# STM32F429x register map
File version: 1.0
Registers are 32-bit, read-write, reset 0x0 unless marked. A register's access mark holds for its fields unless they carry their own. Offsets are from the block's base; [hi:lo] are bit positions; {n}, {i} and the like mark numbered series; 'fields as' and 'values as' point back to an identical list.

## NVIC — Nested Vectored Interrupt Controller
Base 0xE000E000
0x04 ICTR ro — Interrupt Controller Type Register
  [3:0] INTLINESNUM — Total number of interrupt lines in groups
{0x100+4i} ISER{i} (i=0..2) — Interrupt Set-Enable Register
  [31:0] SETENA
{0x180+4i} ICER{i} (i=0..2) — Interrupt Clear-Enable Register
  [31:0] CLRENA
{0x200+4i} ISPR{i} (i=0..2) — Interrupt Set-Pending Register
  [31:0] SETPEND
{0x280+4i} ICPR{i} (i=0..2) — Interrupt Clear-Pending Register
  [31:0] CLRPEND
{0x300+4i} IABR{i} ro (i=0..2) — Interrupt Active Bit Register
  [31:0] ACTIVE
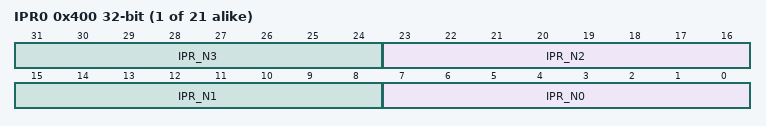
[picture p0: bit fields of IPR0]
{0x400+4i} IPR{i} (i=0..20) — Interrupt Priority Register
  [8n+7:8n] IPR_N{n} (n=0..3)
0xF00 STIR wo — Software Triggered Interrupt Register
  [8:0] INTID — interrupt to be triggered

## FLASH
Base 0x40023C00
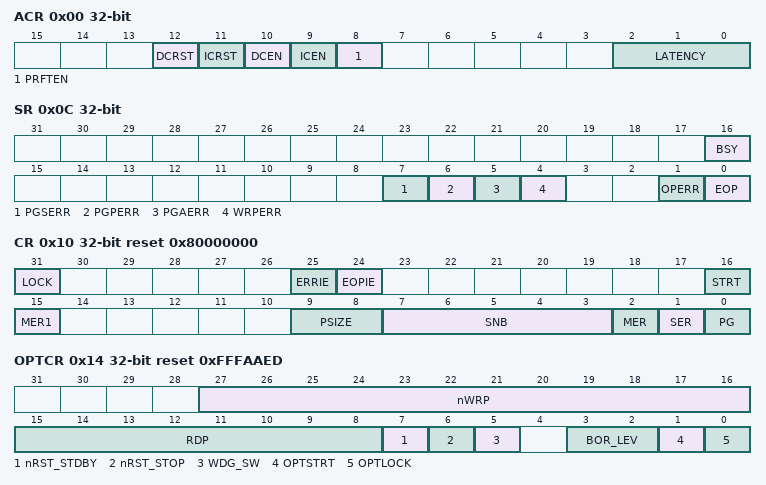
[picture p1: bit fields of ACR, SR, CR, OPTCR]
0x00 ACR access per field — Flash access control register
  [12] DCRST rw — Data cache reset
  [11] ICRST wo — Instruction cache reset
  [10] DCEN rw — Data cache enable
  [9] ICEN rw — Instruction cache enable
  [8] PRFTEN rw — Prefetch enable
  [2:0] LATENCY rw
0x04 KEYR wo — Flash key register
  [31:0] KEY — FPEC key
0x08 OPTKEYR wo — Flash option key register
  [31:0] OPTKEY — Option byte key
0x0C SR access per field — Status register
  [16] BSY ro — Busy
  [7] PGSERR rw — Programming sequence error
  [6] PGPERR rw — Programming parallelism error
  [5] PGAERR rw — Programming alignment error
  [4] WRPERR rw — Write protection error
  [1] OPERR rw — Operation error
  [0] EOP rw — End of operation
0x10 CR reset 0x80000000 — Control register
  [31] LOCK
  [25] ERRIE — Error interrupt enable
  [24] EOPIE — End of operation interrupt enable
  [16] STRT — Start
  [15] MER1 — Mass Erase of sectors 12 to 23
  [9:8] PSIZE — Program size
  [7:3] SNB — Sector number
  [2] MER — Mass Erase of sectors 0 to 11
  [1] SER — Sector Erase
  [0] PG — Programming
0x14 OPTCR reset 0xFFFAAED — Flash option control register
  [27:16] nWRP — Not write protect
  [15:8] RDP — Read protect
  [7] nRST_STDBY — nRST_STDBY User option bytes
  [6] nRST_STOP — nRST_STOP User option bytes
  [5] WDG_SW — WDG_SW User option bytes
  [3:2] BOR_LEV — BOR reset Level
  [1] OPTSTRT — Option start
  [0] OPTLOCK — Option lock
0x18 OPTCR1 reset 0xFFF0000 — Flash option control register 1
  [27:16] nWRP — Not write protect

## EXTI — External interrupt/event controller
Base 0x40013C00
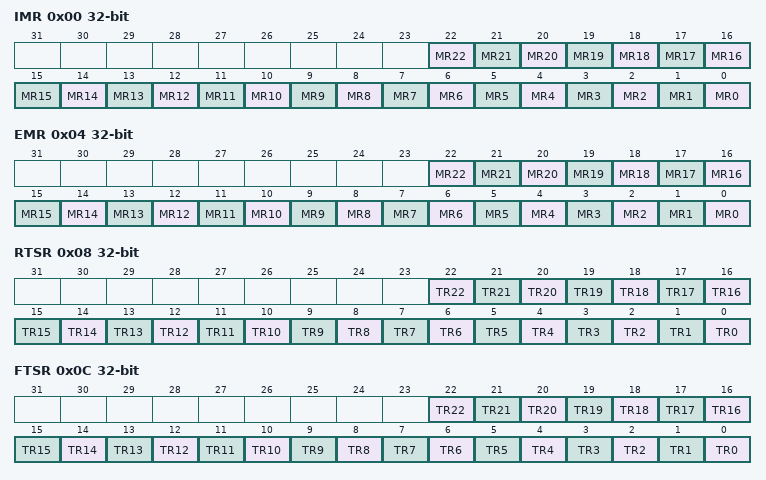
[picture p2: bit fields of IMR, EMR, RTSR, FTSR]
0x00 IMR — Interrupt mask register (EXTI_IMR)
  [n] MR{n} (n=0..22) — Interrupt Mask on line {n}
0x04 EMR — Event mask register (EXTI_EMR)
  [n] MR{n} (n=0..22) — Event Mask on line {n}
0x08 RTSR — Rising Trigger selection register (EXTI_RTSR)
  [n] TR{n} (n=0..22) — Rising trigger event configuration of line {n}
0x0C FTSR — Falling Trigger selection register (EXTI_FTSR)
  [n] TR{n} (n=0..22) — Falling trigger event configuration of line {n}
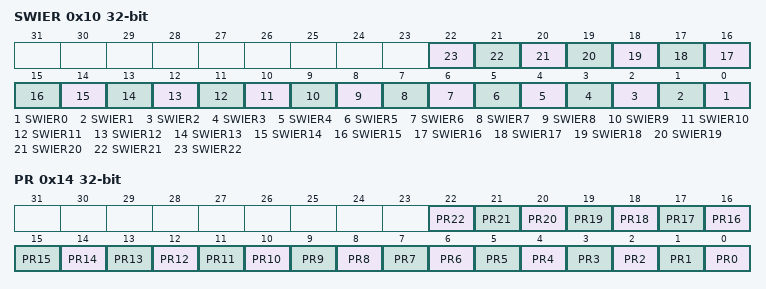
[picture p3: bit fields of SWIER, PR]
0x10 SWIER — Software interrupt event register (EXTI_SWIER)
  [n] SWIER{n} (n=0..22) — Software Interrupt on line {n}
0x14 PR — Pending register (EXTI_PR)
  [n] PR{n} (n=0..22) — Pending bit {n}

## OTG_HS_PWRCLK — USB on the go high speed
Base 0x40040E00
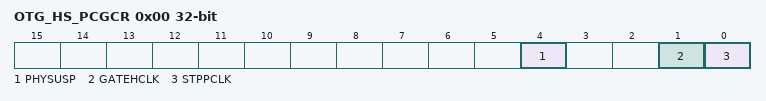
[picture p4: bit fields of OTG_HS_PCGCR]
0x00 OTG_HS_PCGCR — Power and clock gating control register
  [4] PHYSUSP — PHY suspended
  [1] GATEHCLK
  [0] STPPCLK — Stop PHY clock

## DMA2D — DMA2D controller
Base 0x4002B000
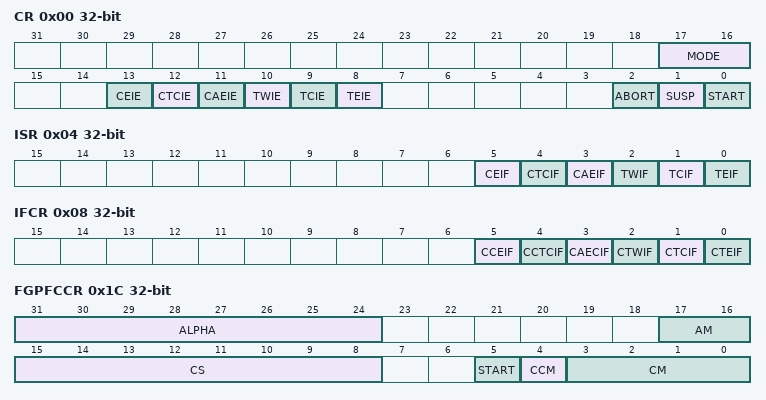
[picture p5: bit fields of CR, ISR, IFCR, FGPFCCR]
0x00 CR — control register
  [17:16] MODE — DMA2D mode
  [13] CEIE — Configuration Error Interrupt Enable
  [12] CTCIE — CLUT transfer complete interrupt enable
  [11] CAEIE — CLUT access error interrupt enable
  [10] TWIE — Transfer watermark interrupt enable
  [9] TCIE — Transfer complete interrupt enable
  [8] TEIE — Transfer error interrupt enable
  [2] ABORT
  [1] SUSP — Suspend
  [0] START
0x04 ISR ro — Interrupt Status Register
  [5] CEIF — Configuration error interrupt flag
  [4] CTCIF — CLUT transfer complete interrupt flag
  [3] CAEIF — CLUT access error interrupt flag
  [2] TWIF — Transfer watermark interrupt flag
  [1] TCIF — Transfer complete interrupt flag
  [0] TEIF — Transfer error interrupt flag
0x08 IFCR — interrupt flag clear register
  [5] CCEIF — Clear configuration error interrupt flag
  [4] CCTCIF — Clear CLUT transfer complete interrupt flag
  [3] CAECIF — Clear CLUT access error interrupt flag
  [2] CTWIF — Clear transfer watermark interrupt flag
  [1] CTCIF — Clear transfer complete interrupt flag
  [0] CTEIF — Clear Transfer error interrupt flag
0x0C FGMAR — foreground memory address register
  [31:0] MA — Memory address
0x10 FGOR — foreground offset register
  [13:0] LO — Line offset
0x14 BGMAR — background memory address register
  [31:0] MA — Memory address
0x18 BGOR — background offset register
  [13:0] LO — Line offset
0x1C FGPFCCR — foreground PFC control register
  [31:24] ALPHA — Alpha value
  [17:16] AM — Alpha mode
  [15:8] CS — CLUT size
  [5] START
  [4] CCM — CLUT color mode
  [3:0] CM — Color mode
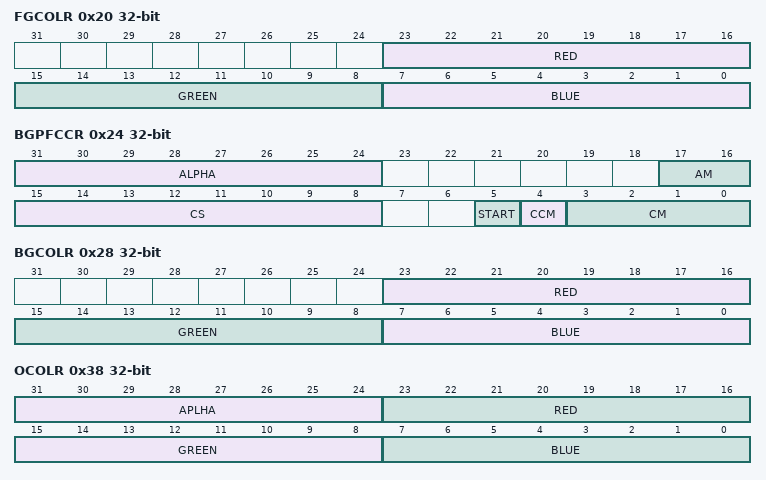
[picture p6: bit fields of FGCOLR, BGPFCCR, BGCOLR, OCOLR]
0x20 FGCOLR — foreground color register
  [23:16] RED — Red Value
  [15:8] GREEN — Green Value
  [7:0] BLUE — Blue Value
0x24 BGPFCCR — background PFC control register
  [31:24] ALPHA — Alpha value
  [17:16] AM — Alpha mode
  [15:8] CS — CLUT size
  [5] START
  [4] CCM — CLUT Color mode
  [3:0] CM — Color mode
0x28 BGCOLR — background color register
  fields as FGCOLR
0x2C FGCMAR — foreground CLUT memory address register
  [31:0] MA — Memory Address
0x30 BGCMAR — background CLUT memory address register
  [31:0] MA — Memory address
0x34 OPFCCR — output PFC control register
  [2:0] CM — Color mode
0x38 OCOLR — output color register
  [31:24] APLHA — Alpha Channel Value
  [23:16] RED — Red Value
  [15:8] GREEN — Green Value
  [7:0] BLUE — Blue Value
0x3C OMAR — output memory address register
  [31:0] MA — Memory Address
0x40 OOR — output offset register
  [13:0] LO — Line Offset
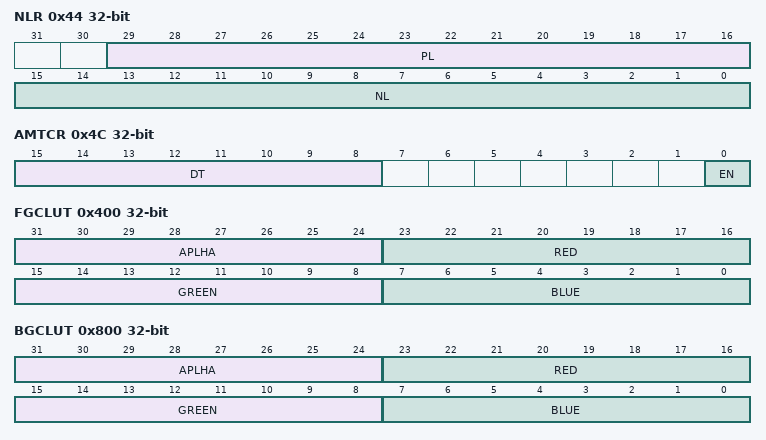
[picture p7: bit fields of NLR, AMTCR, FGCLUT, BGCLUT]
0x44 NLR — number of line register
  [29:16] PL — Pixel per lines
  [15:0] NL — Number of lines
0x48 LWR — line watermark register
  [15:0] LW — Line watermark
0x4C AMTCR — AHB master timer configuration register
  [15:8] DT — Dead Time
  [0] EN — Enable
0x400 FGCLUT
  [31:24] APLHA, [23:16] RED, [15:8] GREEN, [7:0] BLUE
0x800 BGCLUT
  [31:24] APLHA, [23:16] RED, [15:8] GREEN, [7:0] BLUE

## PWR — Power control
Base 0x40007000
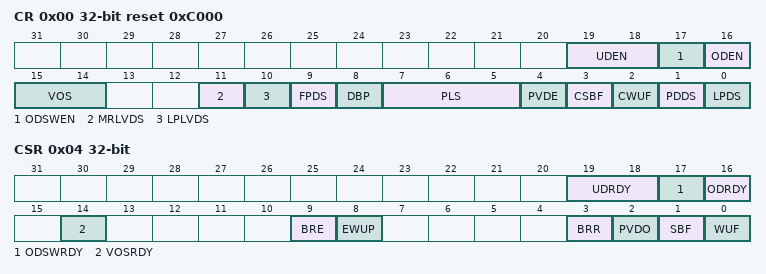
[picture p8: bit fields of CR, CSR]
0x00 CR reset 0xC000 — power control register
  [19:18] UDEN — Under-drive enable in stop mode
  [17] ODSWEN — Over-drive switching enabled
  [16] ODEN — Over-drive enable
  [15:14] VOS — Regulator voltage scaling output selection
  [11] MRLVDS — Main regulator low voltage in deepsleep mode
  [10] LPLVDS — Low-Power Regulator Low Voltage in deepsleep
  [9] FPDS — Flash power down in Stop mode
  [8] DBP — Disable backup domain write protection
  [7:5] PLS — PVD level selection
  [4] PVDE — Power voltage detector enable
  [3] CSBF — Clear standby flag
  [2] CWUF — Clear wakeup flag
  [1] PDDS — Power down deepsleep
  [0] LPDS — Low-power deep sleep
0x04 CSR access per field — power control/status register
  [19:18] UDRDY rw — Under-drive ready flag
  [17] ODSWRDY ro — Over-drive mode switching ready
  [16] ODRDY ro — Over-drive mode ready
  [14] VOSRDY rw — Regulator voltage scaling output selection ready bit
  [9] BRE rw — Backup regulator enable
  [8] EWUP rw — Enable WKUP pin
  [3] BRR ro — Backup regulator ready
  [2] PVDO ro — PVD output
  [1] SBF ro — Standby flag
  [0] WUF ro — Wakeup flag
